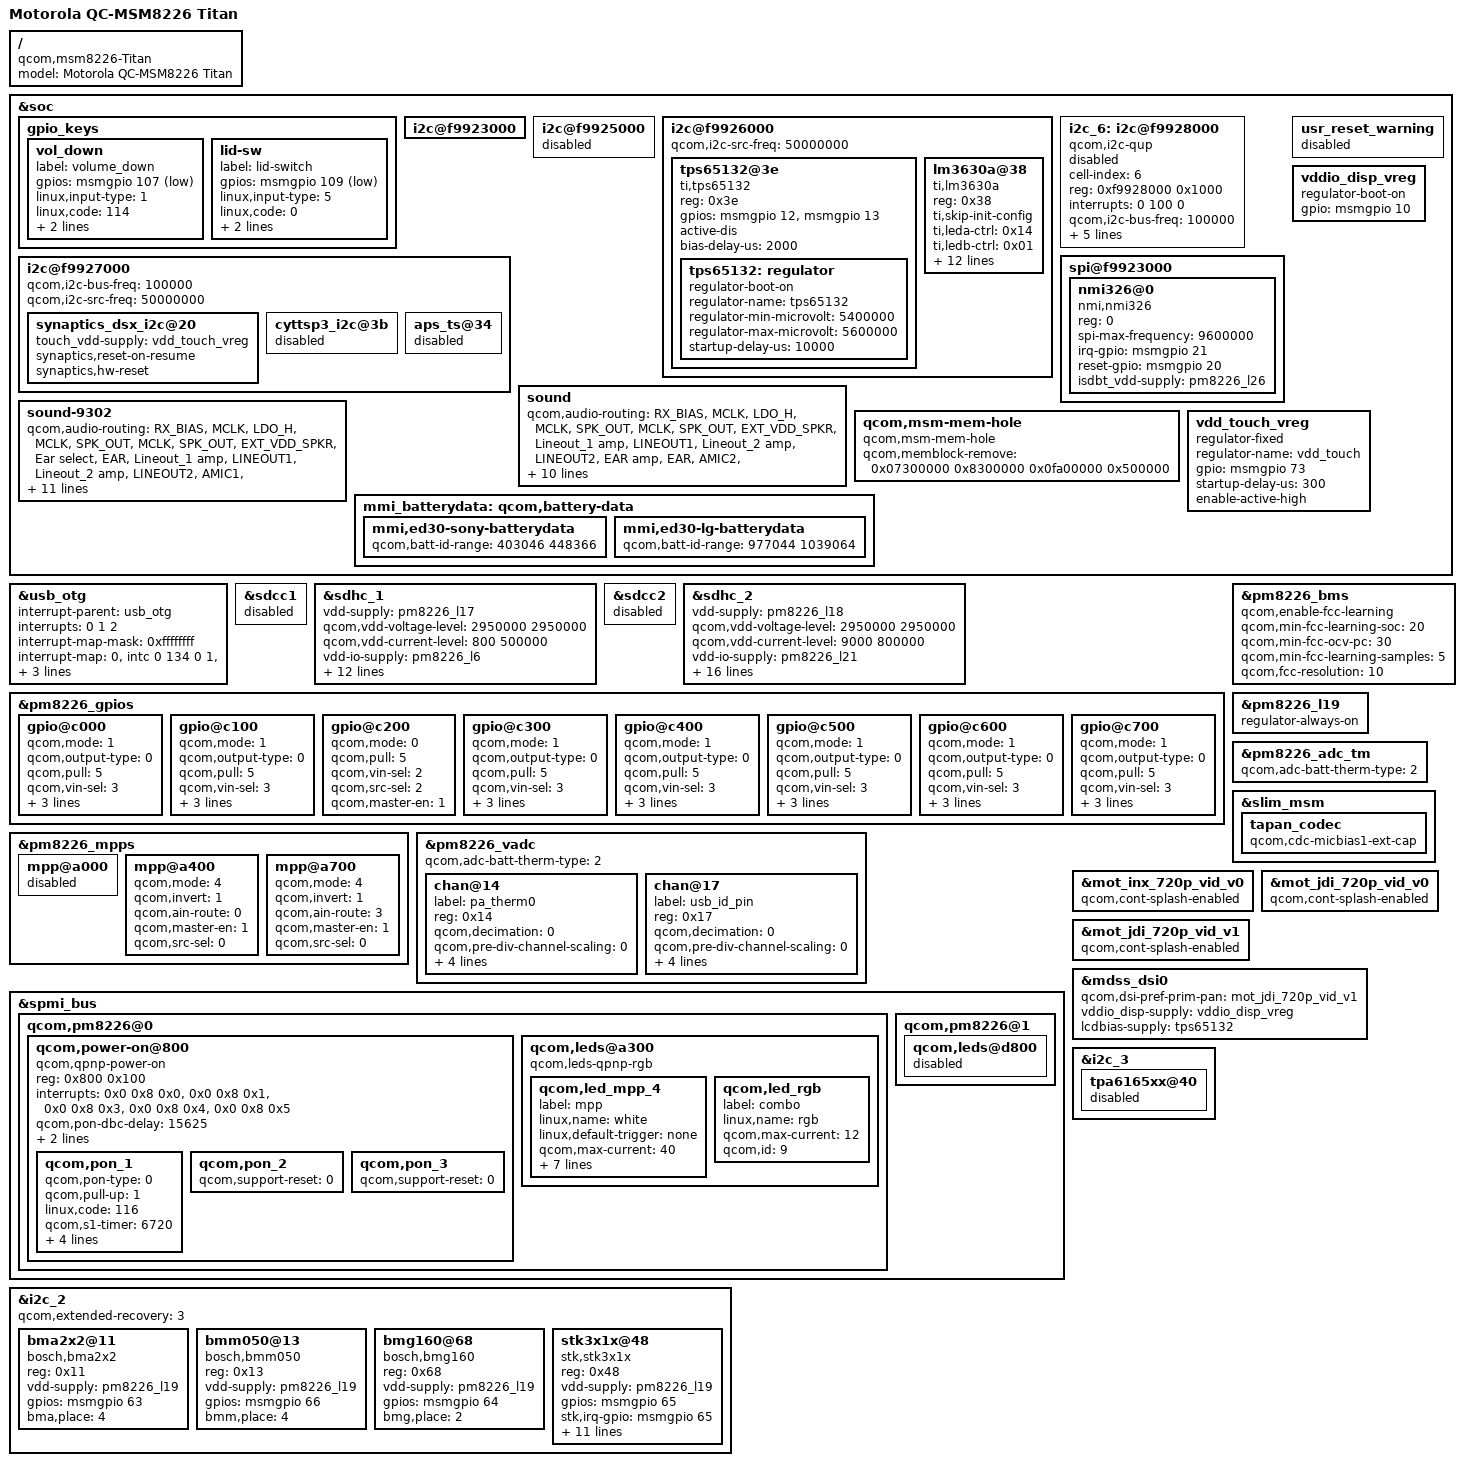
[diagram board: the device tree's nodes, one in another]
/* Copyright (c) 2013, The Linux Foundation. All rights reserved.
 * Copyright (c) 2014 Motorola Mobility LLC
 *
 * This program is free software; you can redistribute it and/or modify
 * it under the terms of the GNU General Public License version 2 and
 * only version 2 as published by the Free Software Foundation.
 *
 * This program is distributed in the hope that it will be useful,
 * but WITHOUT ANY WARRANTY; without even the implied warranty of
 * MERCHANTABILITY or FITNESS FOR A PARTICULAR PURPOSE.  See the
 * GNU General Public License for more details.
 */

/include/ "msm8226-moto-common.dtsi"
/include/ "msm8226-titan-gpiomux.dtsi"
/include/ "dsi-panel-mot-dummy-qhd-video.dtsi"
/include/ "dsi-panel-mot-inx-720p-video.dtsi"
/include/ "dsi-panel-mot-jdi-720p-video.dtsi"

/ {
	model = "Motorola QC-MSM8226 Titan";
	compatible = "qcom,msm8226-Titan",
		     "qcom,msm8226-moto",
		     "qcom,msm8226";
};

&soc {
	gpio_keys {

		vol_down {
			label = "volume_down";
			gpios = <&msmgpio 107 0x1>;
			linux,input-type = <1>;
			linux,code = <114>;
			gpio-key,wakeup;
			debounce-interval = <15>;
		};

		lid-sw {
			label = "lid-switch";
			gpios = <&msmgpio 109 0x1>;
			linux,input-type = <5>;
			linux,code = <0>;
			gpio-key,wakeup;
			debounce-interval = <15>;
		};
	};

	i2c@f9923000 {
		/delete-node/ synaptics_dsx_i2c@20;
	};

	i2c@f9925000 { /* BLSP1 QUP3 */
		status = "disabled";
		/delete-node/ tps65132@3e;
	};

	i2c@f9926000 { /* BLSP-1 QUP-4 */
		qcom,i2c-src-freq = <50000000>;
		tps65132@3e {
			compatible = "ti,tps65132";
			reg = <0x3e>;
			gpios = <&msmgpio 12 0x0>, <&msmgpio 13 0x0>;
			active-dis;
			bias-delay-us = <2000>;
			tps65132: regulator {
				regulator-boot-on;
				regulator-name = "tps65132";
				regulator-min-microvolt = <5400000>;
				regulator-max-microvolt = <5600000>;
				startup-delay-us = <10000>;
			};
		};
		lm3630a@38 {
			status = "okay";
			compatible = "ti,lm3630a";
			reg = <0x38>;
			ti,skip-init-config;
			/* 2 string LEDs controled by LEDA */
			ti,leda-ctrl = <0x14>;
			ti,ledb-ctrl = <0x01>;
			ti,leda-max-brt = <0xff>;
			ti,ledb-max-brt = <0xff>;
			ti,leda-init-brt = <0xff>;
			ti,ledb-init-brt = <0xff>;
			ti,leda-max-cur = <0x14>;
			ti,ledb-max-cur = <0x14>;
			ti,boost-ctrl = <0x20>;
			ti,config = <0x09>;
			ti,irq-gpio = <&msmgpio 4 0>;
			ti,hwen-gpio = <&msmgpio 5 0>;
			ti,vddio-name = "vddio_bl";
			vddio_bl-supply = <&pm8226_l6>;
		};
	};

	i2c@f9927000 {
		status = "okay";
		qcom,i2c-bus-freq = <100000>;
		qcom,i2c-src-freq = <50000000>;

		synaptics_dsx_i2c@20 {
			touch_vdd-supply = <&vdd_touch_vreg>;
			synaptics,reset-on-resume;
			synaptics,hw-reset;
			/delete-property/ synaptics,normal-mode;
		};

		cyttsp3_i2c@3b {
			status = "disabled";
		};

		aps_ts@34 {
			status = "disabled";
		};

	};

	i2c_6: i2c@f9928000 { /* BLSP-1 QUP-6 */
		cell-index = <6>;
		compatible = "qcom,i2c-qup";
		reg = <0xf9928000 0x1000>;
		reg-names = "qup_phys_addr";
		interrupts = <0 100 0>;
		interrupt-names = "qup_err_intr";
		qcom,i2c-bus-freq = <100000>;
		qcom,i2c-src-freq = <19200000>;
		qcom,sda-gpio = <&msmgpio 22 0>;
		qcom,scl-gpio = <&msmgpio 23 0>;
		qcom,extended-recovery = <3>;
		qcom,master-id = <86>;
		status = "disabled";
	};


	spi@f9923000 {
		status = "ok";
		nmi326@0 {
			compatible = "nmi,nmi326";
			reg = <0>;
			spi-max-frequency = <9600000>;
			irq-gpio = <&msmgpio 21 0>;
			reset-gpio = <&msmgpio 20 0>;
			isdbt_vdd-supply = <&pm8226_l26>;
		};
	};


	sound {
		qcom,audio-routing =
			"RX_BIAS", "MCLK",
			"LDO_H", "MCLK",
			"SPK_OUT", "MCLK",
			"SPK_OUT", "EXT_VDD_SPKR",
			"Lineout_1 amp", "LINEOUT1",
			"Lineout_2 amp", "LINEOUT2",
			"EAR amp", "EAR",
			"AMIC2", "MIC BIAS2 External",
			"MIC BIAS2 External", "Headset Mic",
			"AMIC1", "MIC BIAS1 External",
			"MIC BIAS1 External", "Handset Mic",
			"AMIC3", "MIC BIAS1 External",
			"MIC BIAS1 External", "Handset Mic";


		fih,cdc-lineout-topspkr-gpios = <&msmgpio 50 0x1>;
		fih,cdc-lineout-botspkr-gpios = <&msmgpio 51 0x1>;
		fih,cdc-spk-rcv-sel-gpios = <&msmgpio 52 0>;

		status = "ok";
	};

	sound-9302 {
		qcom,audio-routing =
			"RX_BIAS", "MCLK",
			"LDO_H", "MCLK",
			"SPK_OUT", "MCLK",
			"SPK_OUT", "EXT_VDD_SPKR",
			"Ear select", "EAR",
			"Lineout_1 amp", "LINEOUT1",
			"Lineout_2 amp", "LINEOUT2",
			"AMIC1", "MIC BIAS1 External",
			"MIC BIAS1 External", "Handset Mic",
			"AMIC2", "MIC BIAS2 External",
			"MIC BIAS2 External", "Headset Mic",
			"AMIC3", "MIC BIAS1 External",
			"MIC BIAS1 External", "Handset Mic";

		qcom,cdc-mclk-gpios = <&pm8226_gpios 1 0>;

		fih,cdc-lineout-topspkr-gpios = <&msmgpio 50 0x1>;
		fih,cdc-lineout-botspkr-gpios = <&msmgpio 51 0x1>;
		fih,cdc-spk-rcv-sel-gpios = <&msmgpio 52 0>;
		status = "ok";
	};


	qcom,msm-mem-hole {
		compatible = "qcom,msm-mem-hole";
		qcom,memblock-remove = <0x07300000 0x8300000
					0x0fa00000 0x500000>; /* Address and size of the hole */
	};

	usr_reset_warning {
		status = "disabled";
	};

	vddio_disp_vreg: vddio_disp_vreg {
		regulator-boot-on;
		gpio = <&msmgpio 10 0x0>;
		/delete-property/ parent-supply;
	};

	vdd_touch_vreg: vdd_touch_vreg {
		compatible = "regulator-fixed";
		regulator-name = "vdd_touch";
		gpio = <&msmgpio 73 0x0>;
		startup-delay-us = <300>;
		enable-active-high;
	};

	mmi_batterydata: qcom,battery-data {
		mmi,ed30-sony-batterydata {
			qcom,batt-id-range = <403046 448366>;
		};
		mmi,ed30-lg-batterydata {
			qcom,batt-id-range = <977044 1039064>;
		};
	};

};

&usb_otg {
	#address-cells = <0>;
	interrupt-parent = <&usb_otg>;
	interrupts = <0 1 2>;
	#interrupt-cells = <1>;
	interrupt-map-mask = <0xffffffff>;
	interrupt-map = <0 &intc 0 134 0
			1 &intc 0 140 0
			2 &spmi_bus 0x0 0x0 0x9 0x0>;
	interrupt-names = "core_irq", "async_irq", "pmic_id_irq";
	qcom,hsusb-otg-mode = <3>;
	vbus_otg-supply = <&pm8226_chg_otg>;
	/delete-property/ otg,id_flt_gpio;
	/delete-property/ otg,id_gnd_gpio;
};



&sdcc1 {
	status = "disabled";
};

&sdhc_1 {
	vdd-supply = <&pm8226_l17>;
	qcom,vdd-voltage-level = <2950000 2950000>;
	qcom,vdd-current-level = <800 500000>;

	vdd-io-supply = <&pm8226_l6>;
	qcom,vdd-io-always-on;
	qcom,vdd-io-voltage-level = <1800000 1800000>;
	qcom,vdd-io-current-level = <250 154000>;

	qcom,pad-pull-on = <0x0 0x3 0x3>; /* no-pull, pull-up, pull-up */
	qcom,pad-pull-off = <0x0 0x3 0x3>; /* no-pull, pull-up, pull-up */
	qcom,pad-drv-on = <0x3 0x3 0x3>; /* 8mA, 8mA, 8mA */
	qcom,pad-drv-off = <0x0 0x0 0x0>; /* 2mA, 2mA, 2mA */

	qcom,clk-rates = <400000 25000000 50000000 100000000>;
	qcom,bus-speed-mode = "DDR50", "DDR_1p8v";
	qcom,nonremovable;
	qcom,emmc;

	status = "ok";
};

&sdcc2 {
	status = "disable";
};


&sdhc_2 {
	vdd-supply = <&pm8226_l18>;
	qcom,vdd-voltage-level = <2950000 2950000>;
	qcom,vdd-current-level = <9000 800000>;

	vdd-io-supply = <&pm8226_l21>;
	qcom,vdd-io-voltage-level = <1800000 2950000>;
	qcom,vdd-io-current-level = <6 22000>;

	qcom,pad-pull-on = <0x0 0x3 0x3>; /* no-pull, pull-up, pull-up */
	qcom,pad-pull-off = <0x0 0x3 0x3>; /* no-pull, pull-up, pull-up */
	qcom,pad-drv-on = <0x3 0x3 0x3>; /* 8mA, 8mA, 8mA */
	qcom,pad-drv-off = <0x0 0x0 0x0>; /* 2mA, 2mA, 2mA */

	qcom,clk-rates = <400000 23076923 50000000 100000000 120000000>;
	qcom,bus-speed-mode = "SDR12_1p8v", "SDR25_1p8v", "SDR50_1p8v", "DDR_1p8v", "SDR104_1p8v";

	#address-cells = <0>;
	interrupt-parent = <&sdhc_2>;
	interrupts = <0 1 2>;
	#interrupt-cells = <1>;
	interrupt-map-mask = <0xffffffff>;
	interrupt-map = <0 &intc 0 125 0
			 1 &intc 0 221 0
			2 &msmgpio 38 0x3>;
	interrupt-names = "hc_irq", "pwr_irq", "status_irq";
	cd-gpios = <&msmgpio 38 0x1>;

	status = "ok";
};

&pm8226_gpios {

	gpio@c000 { /* GPIO 1 */
		 /* XO_PMIC_CDC_MCLK enable for tapan codec */
		qcom,mode = <1>;                /* Digital output */
		qcom,output-type = <0>; /* CMOS logic */
		qcom,pull = <5>;                /* QPNP_PIN_PULL_NO*/
		qcom,vin-sel = <3>;             /* QPNP_PIN_VIN3 */
		qcom,out-strength = <3>;/* QPNP_PIN_OUT_STRENGTH_HIGH */
		qcom,src-sel = <2>;             /* QPNP_PIN_SEL_FUNC_1 */
		qcom,master-en = <1>;   /* Enable GPIO */
	};

	gpio@c100 { /* GPIO 2 */
		qcom,mode = <1>;
		qcom,output-type = <0>;
		qcom,pull = <5>;
		qcom,vin-sel = <3>;
		qcom,out-strength = <3>;
		qcom,src-sel = <2>;
		qcom,master-en = <1>;
	};

	gpio@c200 { /* GPIO 3 */
		qcom,mode = <0>;                /* QPNP_PIN_MODE_DIG_IN */
		qcom,pull = <5>;                /* QPNP_PIN_PULL_NO */
		qcom,vin-sel = <2>;             /* QPNP_PIN_VIN2 */
		qcom,src-sel = <2>;             /* QPNP_PIN_SEL_FUNC_1 */
		qcom,master-en = <1>;
	};

	gpio@c300 { /* GPIO 4 */
		qcom,mode = <1>;                /* Digital output */
		qcom,output-type = <0>; /* CMOS logic */
		qcom,pull = <5>;                /* QPNP_PIN_PULL_NO*/
		qcom,vin-sel = <3>;             /* QPNP_PIN_VIN3 */
		qcom,out-strength = <3>;/* QPNP_PIN_OUT_STRENGTH_HIGH */
		qcom,src-sel = <0>;             /* QPNP_PIN_SEL_FUNC_1 */
		qcom,master-en = <1>;   /* Enable GPIO */
	};

	gpio@c400 { /* GPIO 5 */
		qcom,mode = <1>;                /* Digital output */
		qcom,output-type = <0>; /* CMOS logic */
		qcom,pull = <5>;                /* QPNP_PIN_PULL_NO*/
		qcom,vin-sel = <3>;             /* QPNP_PIN_VIN3 */
		qcom,out-strength = <3>;/* QPNP_PIN_OUT_STRENGTH_HIGH */
		qcom,src-sel = <0>;             /* QPNP_PIN_SEL_FUNC_1 */
		qcom,master-en = <1>;   /* Enable GPIO */
	};

	gpio@c500 { /* GPIO 6 */
		qcom,mode = <1>;                /* Digital output */
		qcom,output-type = <0>; /* CMOS logic */
		qcom,pull = <5>;                /* QPNP_PIN_PULL_NO*/
		qcom,vin-sel = <3>;             /* QPNP_PIN_VIN3 */
		qcom,out-strength = <3>;/* QPNP_PIN_OUT_STRENGTH_HIGH */
		qcom,src-sel = <0>;             /* QPNP_PIN_SEL_FUNC_1 */
		qcom,master-en = <1>;   /* Enable GPIO */
	};

	gpio@c600 { /* GPIO 7 */
		qcom,mode = <1>;                /* Digital output */
		qcom,output-type = <0>; /* CMOS logic */
		qcom,pull = <5>;                /* QPNP_PIN_PULL_NO*/
		qcom,vin-sel = <3>;             /* QPNP_PIN_VIN3 */
		qcom,out-strength = <3>;/* QPNP_PIN_OUT_STRENGTH_HIGH */
		qcom,src-sel = <0>;             /* QPNP_PIN_SEL_FUNC_1 */
		qcom,master-en = <1>;   /* Enable GPIO */
	};

	gpio@c700 { /* GPIO 8 */
		qcom,mode = <1>;                /* Digital output */
		qcom,output-type = <0>; /* CMOS logic */
		qcom,pull = <5>;                /* QPNP_PIN_PULL_NO*/
		qcom,vin-sel = <3>;             /* QPNP_PIN_VIN3 */
		qcom,out-strength = <3>;/* QPNP_PIN_OUT_STRENGTH_HIGH */
		qcom,src-sel = <3>;             /* QPNP_PIN_SEL_FUNC_2 */
		qcom,master-en = <1>;   /* Enable GPIO */
	};
};

&pm8226_mpps {
	mpp@a000 { /* MPP 1 */
		status = "disabled";
	};

	mpp@a400 { /* MPP 5 */
		/* PA_THERM0 config */
		qcom,mode = <4>; /* AIN input */
		qcom,invert = <1>; /* Enable MPP */
		qcom,ain-route = <0>; /* AMUX 5 */
		qcom,master-en = <1>;
		qcom,src-sel = <0>; /* Function constant */
	};

	mpp@a700 { /* MPP 8 */
		/* USB_ID config */
		qcom,mode = <4>; /* AIN input */
		qcom,invert = <1>; /* Enable MPP */
		qcom,ain-route = <3>; /* AMUX 8 */
		qcom,master-en = <1>;
		qcom,src-sel = <0>; /* Function constant */
	};
};

&pm8226_bms {
	status = "ok";
	qcom,enable-fcc-learning;
	qcom,min-fcc-learning-soc = <20>;
	qcom,min-fcc-ocv-pc = <30>;
	qcom,min-fcc-learning-samples = <5>;
	qcom,fcc-resolution = <10>;
};


&pm8226_l19{
	regulator-always-on; //TODO, really needs L19 always on  ?
};

&pm8226_vadc {
	qcom,adc-batt-therm-type = <2>;
	chan@14 {
		label = "pa_therm0";
		reg = <0x14>;
		qcom,decimation = <0>;
		qcom,pre-div-channel-scaling = <0>;
		qcom,calibration-type = "ratiometric";
		qcom,scale-function = <2>;
		qcom,hw-settle-time = <2>;
		qcom,fast-avg-setup = <0>;
	};

	chan@17 {
		label = "usb_id_pin";
		reg = <0x17>;
		qcom,decimation = <0>;
		qcom,pre-div-channel-scaling = <0>;
		qcom,calibration-type = "ratiometric";
		qcom,scale-function = <0>;
		qcom,hw-settle-time = <2>;
		qcom,fast-avg-setup = <0>;
	};

};

&pm8226_adc_tm {

	qcom,adc-batt-therm-type = <2>;
	/delete-node/ chan@17;
};

&slim_msm {
	tapan_codec {
		qcom,cdc-micbias1-ext-cap;
	};
};

&spmi_bus {
	qcom,pm8226@0 {
		qcom,power-on@800 {
			compatible = "qcom,qpnp-power-on";
			reg = <0x800 0x100>;
			interrupts = <0x0 0x8 0x0>,
				     <0x0 0x8 0x1>,
				     <0x0 0x8 0x3>,
				     <0x0 0x8 0x4>,
				     <0x0 0x8 0x5>;
			interrupt-names = "kpdpwr", "resin", "kpdpwr-bark",
					"resin-bark", "kpdpwr-resin-bark";
			qcom,pon-dbc-delay = <15625>;
			qcom,system-reset;
			qcom,s3-debounce = <32>;

			qcom,pon_1 {
				qcom,pon-type = <0>;
				qcom,pull-up = <1>;
				linux,code = <116>;
				qcom,s1-timer = <6720>;
				qcom,s2-timer = <2000>;
				qcom,s2-type = <7>;
				qcom,support-reset = <1>;
				qcom,use-bark;
			};

			qcom,pon_2 {
				qcom,support-reset = <0>;
			};

			qcom,pon_3 {
				qcom,support-reset = <0>;
			};
		};
		qcom,leds@a300 {
			compatible = "qcom,leds-qpnp-rgb";
			status = "okay";
			qcom,led_mpp_4 {
				label = "mpp";
				linux,name = "white";
				linux,default-trigger = "none";
				qcom,max-current = <40>;
				qcom,current-setting = <5>;
				qcom,id = <6>;
				qcom,mode = "pwm";
				qcom,source-sel = <8>;
				qcom,mode-ctrl = <0x60>;
				qcom,pwm-channel = <0>;
				qcom,pwm-us = <1000>;
			};

			qcom,led_rgb {
				label = "combo";
				linux,name = "rgb";
				qcom,max-current = <12>;
				qcom,id = <9>;
			};
		};
		/delete-node/ qcom,leds@a500;
		/delete-node/ qcom,leds@1000;
	};

	qcom,pm8226@1 {
		qcom,leds@d800 {
			status = "disabled";
		};
	};
};


&mot_inx_720p_vid_v0 {
	qcom,cont-splash-enabled;
};

&mot_jdi_720p_vid_v0 {
	qcom,cont-splash-enabled;
};

&mot_jdi_720p_vid_v1 {
	qcom,cont-splash-enabled;
};

&mdss_dsi0 {
	qcom,dsi-pref-prim-pan = <&mot_jdi_720p_vid_v1>;
	vddio_disp-supply = <&vddio_disp_vreg>;
	lcdbias-supply = <&tps65132>;
};

&i2c_2 {
	qcom,extended-recovery = <3>;

        bma2x2@11 {
                compatible = "bosch,bma2x2";
                reg = <0x11>;
                vdd-supply = <&pm8226_l19>;
                gpios = <&msmgpio 63 0>; /* IRQ */
		bma,place = <4>;
        };

        bmm050@13 {
                compatible = "bosch,bmm050";
                reg = <0x13>;
                vdd-supply = <&pm8226_l19>;
                gpios = <&msmgpio 66 0>; /* IRQ */
		bmm,place = <4>;
        };

        bmg160@68 {
                compatible = "bosch,bmg160";
                reg = <0x68>;
                vdd-supply = <&pm8226_l19>;
                gpios = <&msmgpio 64 0>; /* IRQ */
                bmg,place = <2>;
        };

        stk3x1x@48 {
                compatible = "stk,stk3x1x";
                reg = <0x48>;
                vdd-supply = <&pm8226_l19>;
                gpios = <&msmgpio 65 0>; /* IRQ */
                stk,irq-gpio = <&msmgpio 65 0x0>;
                stk,transmittance = <500>;
                stk,state-reg = <0x00>;
                stk,psctrl-reg = <0x31>;
                stk,alsctrl-reg = <0x38>;
                stk,ledctrl-reg = <0xFF>;
                stk,wait-reg = <0xA7>;
		stk,als_thresh_pct = <5>;
		stk,covered_thresh = <0x0066>;
		stk,uncovered_thresh = <0x003E>;
		stk,recal_thresh = <0x0016>;
		stk,max_noise_fl = <0x0F00>;
        };
};

&i2c_3 {
	tpa6165xx@40 {
		status = "disabled";

	};
};

/include/ "msm8226-camera-sensor-titan.dtsi"
